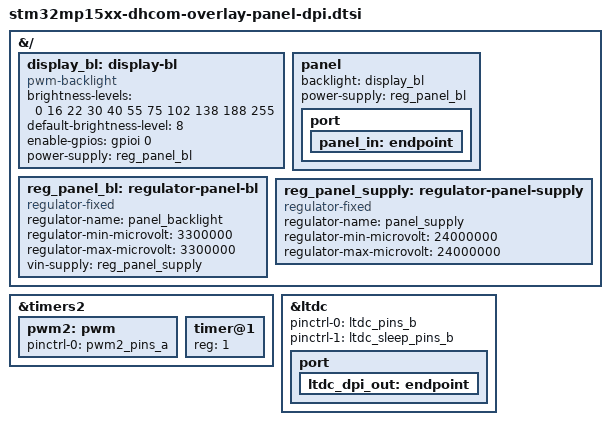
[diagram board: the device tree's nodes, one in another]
// SPDX-License-Identifier: (GPL-2.0+ OR BSD-3-Clause)
/*
 * Copyright (C) 2021 Marek Vasut
 */
#include <dt-bindings/gpio/gpio.h>
#include <dt-bindings/input/input.h>
#include <dt-bindings/interrupt-controller/arm-gic.h>
#include <dt-bindings/pwm/pwm.h>

&{/} {
	display_bl: display-bl {
		compatible = "pwm-backlight";
		brightness-levels = <0 16 22 30 40 55 75 102 138 188 255>;
		default-brightness-level = <8>;
		enable-gpios = <&gpioi 0 GPIO_ACTIVE_HIGH>;
		power-supply = <&reg_panel_bl>;
		status = "okay";
	};

	panel: panel {
		backlight = <&display_bl>;
		power-supply = <&reg_panel_bl>;

		port {
			panel_in: endpoint {
			};
		};
	};

	reg_panel_bl: regulator-panel-bl {
		compatible = "regulator-fixed";
		regulator-name = "panel_backlight";
		regulator-min-microvolt = <3300000>;
		regulator-max-microvolt = <3300000>;
		vin-supply = <&reg_panel_supply>;
	};

	reg_panel_supply: regulator-panel-supply {
		compatible = "regulator-fixed";
		regulator-name = "panel_supply";
		regulator-min-microvolt = <24000000>;
		regulator-max-microvolt = <24000000>;
	};
};

&timers2 {
	#address-cells = <1>;
	#size-cells = <0>;
	status = "okay";

	pwm2: pwm {
		#pwm-cells = <3>;
		pinctrl-0 = <&pwm2_pins_a>;
		pinctrl-names = "default";
		status = "okay";
	};

	timer@1 {
		reg = <1>;
		status = "okay";
	};
};

&ltdc {
	pinctrl-names = "default", "sleep";
	pinctrl-0 = <&ltdc_pins_b>;
	pinctrl-1 = <&ltdc_sleep_pins_b>;
	status = "okay";

	port {
		ltdc_dpi_out: endpoint {
		};
	};
};
